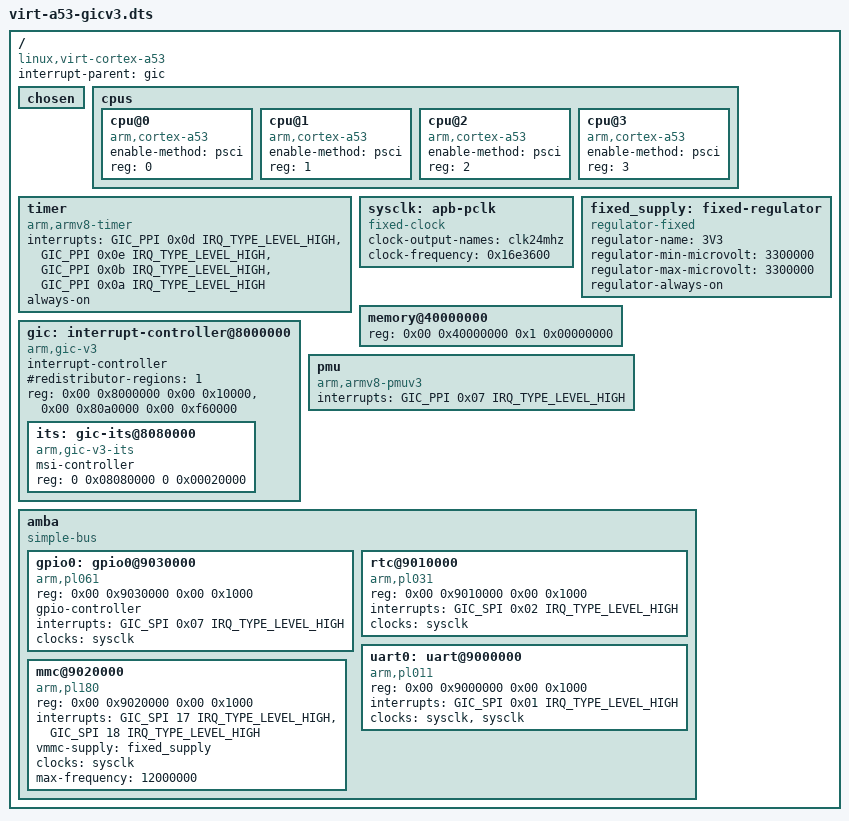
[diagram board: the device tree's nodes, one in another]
#include <dt-bindings/interrupt-controller/arm-gic.h>

/dts-v1/;

/ {
	compatible = "linux,virt-cortex-a53";
	interrupt-parent = <&gic>;
	#size-cells = <0x02>;
	#address-cells = <0x02>;


	chosen {};

	cpus {
		#size-cells = <0x00>;
		#address-cells = <0x01>;

		cpu@0 {
			device_type = "cpu";
			compatible = "arm,cortex-a53";
			enable-method = "psci";
			reg = <0>;
		};

		cpu@1 {
			device_type = "cpu";
			compatible = "arm,cortex-a53";
			enable-method = "psci";
			reg = <1>;
		};

		cpu@2 {
			device_type = "cpu";
			compatible = "arm,cortex-a53";
			enable-method = "psci";
			reg = <2>;
		};

		cpu@3 {
			device_type = "cpu";
			compatible = "arm,cortex-a53";
			enable-method = "psci";
			reg = <3>;
		};
	};

	timer {
		compatible = "arm,armv8-timer", "arm,armv7-timer";
		interrupts = <GIC_PPI 0x0d IRQ_TYPE_LEVEL_HIGH>,
			     <GIC_PPI 0x0e IRQ_TYPE_LEVEL_HIGH>,
			     <GIC_PPI 0x0b IRQ_TYPE_LEVEL_HIGH>,
			     <GIC_PPI 0x0a IRQ_TYPE_LEVEL_HIGH>;
		always-on;
	};

	sysclk: apb-pclk {
		compatible = "fixed-clock";
		clock-output-names = "clk24mhz";
		clock-frequency = <0x16e3600>;
		#clock-cells = <0x00>;
	};

	fixed_supply: fixed-regulator {
		compatible = "regulator-fixed";
		regulator-name = "3V3";
		regulator-min-microvolt = <3300000>;
		regulator-max-microvolt = <3300000>;
		regulator-always-on;
	};

	memory@40000000 {
		device_type = "memory";
		reg = <0x00 0x40000000 0x1 0x00000000>;
	};

	gic: interrupt-controller@8000000 {
		compatible = "arm,gic-v3";
		#interrupt-cells = <3>;
		interrupt-controller;
		#address-cells = <2>;
		#size-cells = <2>;
		ranges;
		#redistributor-regions = <1>;
		reg = <0x00 0x8000000 0x00 0x10000>,
		      <0x00 0x80a0000 0x00 0xf60000>;
		its: gic-its@8080000 {
			compatible = "arm,gic-v3-its";
			msi-controller;
			reg = <0 0x08080000 0 0x00020000>;
		};
	};

	pmu {
		compatible = "arm,armv8-pmuv3";
		interrupts = <GIC_PPI 0x07 IRQ_TYPE_LEVEL_HIGH>;
	};

	amba {
		compatible = "simple-bus";
		#address-cells = <2>;
		#size-cells = <2>;
		ranges;

		gpio0: gpio0@9030000 {
			compatible = "arm,pl061\0arm,primecell";
			reg = <0x00 0x9030000 0x00 0x1000>;
			#gpio-cells = <2>;
			gpio-controller;
			interrupts = <GIC_SPI 0x07 IRQ_TYPE_LEVEL_HIGH>;
			clock-names = "apb_pclk";
			clocks = <&sysclk>;
		};

		rtc@9010000 {
			compatible = "arm,pl031", "arm,primecell";
			reg = <0x00 0x9010000 0x00 0x1000>;
			interrupts = <GIC_SPI 0x02 IRQ_TYPE_LEVEL_HIGH>;
			clock-names = "apb_pclk";
			clocks = <&sysclk>;
		};

		uart0: uart@9000000 {
			compatible = "arm,pl011", "arm,primecell";
			reg = <0x00 0x9000000 0x00 0x1000>;
			interrupts = <GIC_SPI 0x01 IRQ_TYPE_LEVEL_HIGH>;
			clock-names = "uartclk","apb_pclk";
			clocks = <&sysclk &sysclk>;
		};

		mmc@9020000 {
			compatible = "arm,pl180", "arm,primecell";
			reg = <0x00 0x9020000 0x00 0x1000>;
			interrupts =
				<GIC_SPI 17 IRQ_TYPE_LEVEL_HIGH>,
				<GIC_SPI 18 IRQ_TYPE_LEVEL_HIGH>;
			vmmc-supply = <&fixed_supply>;
			clock-names = "apb_pclk";
			clocks = <&sysclk>;
			max-frequency = <12000000>;
		};
	};
};
